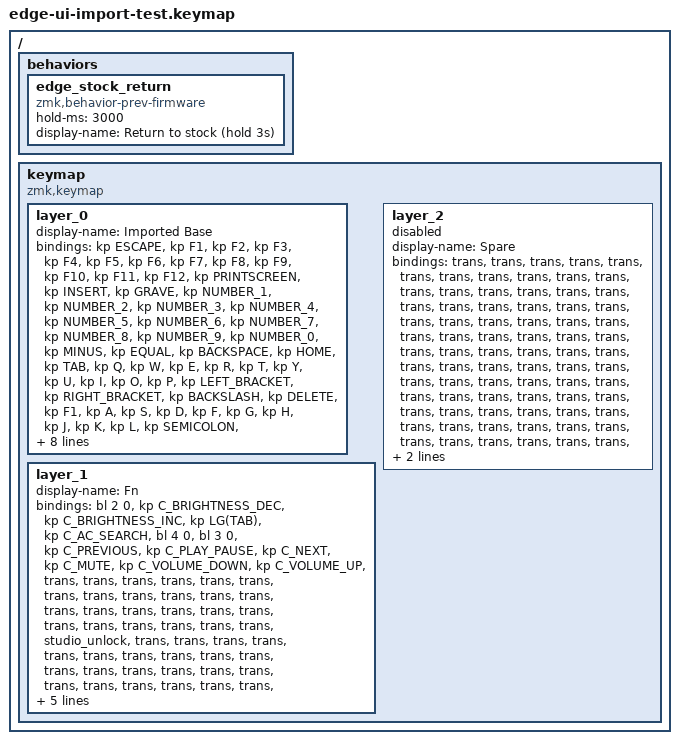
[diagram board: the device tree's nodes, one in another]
/* Exported from the keyboard through ZMK Studio. */
#define ZMK_BEHAVIORS_KEEP_NONE
#define ZMK_BEHAVIORS_KEEP_TOG
#define ZMK_BEHAVIORS_KEEP_TO
#include <behaviors.dtsi>
#include <dt-bindings/zmk/keys.h>
#include <dt-bindings/zmk/backlight.h>
/ {
  behaviors {
    edge_stock_return: edge_stock_return {
      compatible = "zmk,behavior-prev-firmware";
      #binding-cells = <0>;
      hold-ms = <3000>;
      display-name = "Return to stock (hold 3s)";
    };
  };
  keymap {
    compatible = "zmk,keymap";
    layer_0 {
      display-name = "Imported Base";
      bindings = <
        &kp ESCAPE /* Esc */
        &kp F1 /* F1 */
        &kp F2 /* F2 */
        &kp F3 /* F3 */
        &kp F4 /* F4 */
        &kp F5 /* F5 */
        &kp F6 /* F6 */
        &kp F7 /* F7 */
        &kp F8 /* F8 */
        &kp F9 /* F9 */
        &kp F10 /* F10 */
        &kp F11 /* F11 */
        &kp F12 /* F12 */
        &kp PRINTSCREEN /* PrintScreen */
        &kp INSERT /* Insert */
        &kp GRAVE /* ` */
        &kp NUMBER_1 /* 1 */
        &kp NUMBER_2 /* 2 */
        &kp NUMBER_3 /* 3 */
        &kp NUMBER_4 /* 4 */
        &kp NUMBER_5 /* 5 */
        &kp NUMBER_6 /* 6 */
        &kp NUMBER_7 /* 7 */
        &kp NUMBER_8 /* 8 */
        &kp NUMBER_9 /* 9 */
        &kp NUMBER_0 /* 0 */
        &kp MINUS /* - */
        &kp EQUAL /* + */
        &kp BACKSPACE /* BackSpace */
        &kp HOME /* Home */
        &kp TAB /* Tab */
        &kp Q /* Q */
        &kp W /* W */
        &kp E /* E */
        &kp R /* R */
        &kp T /* T */
        &kp Y /* Y */
        &kp U /* U */
        &kp I /* I */
        &kp O /* O */
        &kp P /* P */
        &kp LEFT_BRACKET /* [ */
        &kp RIGHT_BRACKET /* ] */
        &kp BACKSLASH /* \ */
        &kp DELETE /* Delete */
        &kp F1 /* CapsLock */
        &kp A /* A */
        &kp S /* S */
        &kp D /* D */
        &kp F /* F */
        &kp G /* G */
        &kp H /* H */
        &kp J /* J */
        &kp K /* K */
        &kp L /* L */
        &kp SEMICOLON /* ; */
        &kp SINGLE_QUOTE /* ' */
        &kp END /* End */
        &kp RETURN /* Enter */
        &kp PAGE_UP /* PageUp */
        &kp LEFT_SHIFT /* Left Shift */
        &kp Z /* Z */
        &kp X /* X */
        &kp C /* C */
        &kp V /* V */
        &kp B /* B */
        &kp N /* N */
        &kp M /* M */
        &kp COMMA /* , */
        &kp PERIOD /* . */
        &kp SLASH /* / */
        &kp RIGHT_SHIFT /* Right Shift */
        &kp UP_ARROW /* Up */
        &kp LEFT_CONTROL /* Left Ctrl */
        &kp LEFT_GUI /* Left Win */
        &kp LEFT_ALT /* Left Alt */
        &kp SPACE /* Space */
        &kp RIGHT_ARROW /* Right */
        &kp RIGHT_ALT /* Right Alt */
        &mo 1 /* Fn */
        &kp PAGE_DOWN /* PageDown */
        &kp RIGHT_CONTROL /* Right Ctrl */
        &kp LEFT_ARROW /* Left */
        &kp DOWN_ARROW /* Down */
      >;
    };
    layer_1 {
      display-name = "Fn";
      bindings = <
        &bl 2 0 /* Esc */
        &kp C_BRIGHTNESS_DEC /* F1 */
        &kp C_BRIGHTNESS_INC /* F2 */
        &kp LG(TAB) /* F3 */
        &kp C_AC_SEARCH /* F4 */
        &bl 4 0 /* F5 */
        &bl 3 0 /* F6 */
        &kp C_PREVIOUS /* F7 */
        &kp C_PLAY_PAUSE /* F8 */
        &kp C_NEXT /* F9 */
        &kp C_MUTE /* F10 */
        &kp C_VOLUME_DOWN /* F11 */
        &kp C_VOLUME_UP /* F12 */
        &trans /* PrintScreen */
        &trans /* Insert */
        &trans /* ` */
        &trans /* 1 */
        &trans /* 2 */
        &trans /* 3 */
        &trans /* 4 */
        &trans /* 5 */
        &trans /* 6 */
        &trans /* 7 */
        &trans /* 8 */
        &trans /* 9 */
        &trans /* 0 */
        &trans /* - */
        &trans /* + */
        &trans /* BackSpace */
        &trans /* Home */
        &trans /* Tab */
        &trans /* Q */
        &trans /* W */
        &trans /* E */
        &trans /* R */
        &trans /* T */
        &trans /* Y */
        &studio_unlock /* U */
        &trans /* I */
        &trans /* O */
        &trans /* P */
        &trans /* [ */
        &trans /* ] */
        &trans /* \ */
        &trans /* Delete */
        &trans /* CapsLock */
        &trans /* A */
        &trans /* S */
        &trans /* D */
        &trans /* F */
        &trans /* G */
        &trans /* H */
        &trans /* J */
        &trans /* K */
        &trans /* L */
        &trans /* ; */
        &trans /* ' */
        &trans /* End */
        &trans /* Enter */
        &trans /* PageUp */
        &trans /* Left Shift */
        &trans /* Z */
        &trans /* X */
        &trans /* C */
        &trans /* V */
        &trans /* B */
        &trans /* N */
        &trans /* M */
        &trans /* , */
        &trans /* . */
        &trans /* / */
        &trans /* Right Shift */
        &bl 3 0 /* Up */
        &trans /* Left Ctrl */
        &trans /* Left Win */
        &trans /* Left Alt */
        &edge_stock_return /* Space */
        &trans /* Right */
        &trans /* Right Alt */
        &trans /* Fn */
        &trans /* PageDown */
        &trans /* Right Ctrl */
        &trans /* Left */
        &bl 4 0 /* Down */
      >;
    };
    layer_2 {
      display-name = "Spare";
      status = "reserved";
      bindings = <
        &trans /* Esc */
        &trans /* F1 */
        &trans /* F2 */
        &trans /* F3 */
        &trans /* F4 */
        &trans /* F5 */
        &trans /* F6 */
        &trans /* F7 */
        &trans /* F8 */
        &trans /* F9 */
        &trans /* F10 */
        &trans /* F11 */
        &trans /* F12 */
        &trans /* PrintScreen */
        &trans /* Insert */
        &trans /* ` */
        &trans /* 1 */
        &trans /* 2 */
        &trans /* 3 */
        &trans /* 4 */
        &trans /* 5 */
        &trans /* 6 */
        &trans /* 7 */
        &trans /* 8 */
        &trans /* 9 */
        &trans /* 0 */
        &trans /* - */
        &trans /* + */
        &trans /* BackSpace */
        &trans /* Home */
        &trans /* Tab */
        &trans /* Q */
        &trans /* W */
        &trans /* E */
        &trans /* R */
        &trans /* T */
        &trans /* Y */
        &trans /* U */
        &trans /* I */
        &trans /* O */
        &trans /* P */
        &trans /* [ */
        &trans /* ] */
        &trans /* \ */
        &trans /* Delete */
        &trans /* CapsLock */
        &trans /* A */
        &trans /* S */
        &trans /* D */
        &trans /* F */
        &trans /* G */
        &trans /* H */
        &trans /* J */
        &trans /* K */
        &trans /* L */
        &trans /* ; */
        &trans /* ' */
        &trans /* End */
        &trans /* Enter */
        &trans /* PageUp */
        &trans /* Left Shift */
        &trans /* Z */
        &trans /* X */
        &trans /* C */
        &trans /* V */
        &trans /* B */
        &trans /* N */
        &trans /* M */
        &trans /* , */
        &trans /* . */
        &trans /* / */
        &trans /* Right Shift */
        &trans /* Up */
        &trans /* Left Ctrl */
        &trans /* Left Win */
        &trans /* Left Alt */
        &trans /* Space */
        &trans /* Right */
        &trans /* Right Alt */
        &trans /* Fn */
        &trans /* PageDown */
        &trans /* Right Ctrl */
        &trans /* Left */
        &trans /* Down */
      >;
    };
  };
};
